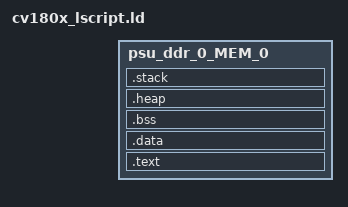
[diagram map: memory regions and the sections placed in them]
/*******************************************************************/
/*                                                                 */
/* This file is automatically generated by linker script generator.*/
/*                                                                 */
/* Version:                                 */
/*                                                                 */
/* Copyright (c) 2010-2016 Xilinx, Inc.  All rights reserved.      */
/*                                                                 */
/* Description : Cortex-A53 Linker Script                          */
/*                                                                 */
/*******************************************************************/
INCLUDE cvi_board_memmap.ld

_STACK_SIZE = DEFINED(_STACK_SIZE) ? _STACK_SIZE : 0x20000;
/* _HEAP_SIZE = DEFINED(_HEAP_SIZE) ? _HEAP_SIZE : 0x1000000; */
/*_HEAP_SIZE =  0x20000;*/

_EL0_STACK_SIZE = DEFINED(_EL0_STACK_SIZE) ? _EL0_STACK_SIZE : 1024;
_EL1_STACK_SIZE = DEFINED(_EL1_STACK_SIZE) ? _EL1_STACK_SIZE : 2048;
_EL2_STACK_SIZE = DEFINED(_EL2_STACK_SIZE) ? _EL2_STACK_SIZE : 1024;

/* Define Memories in the system */

MEMORY
{
   psu_ddr_0_MEM_0 : ORIGIN = CVIMMAP_FREERTOS_ADDR , LENGTH = CVIMMAP_FREERTOS_SIZE
}

/* Specify the default entry point to the program */

/*ENTRY(_vector_table)*/
ENTRY(_start)

/* Define the sections, and where they are mapped in memory */

SECTIONS
{
.text : {
   KEEP (*(.vectors))
   *(.text)
   *(.text.*)
   __rodata_start = .;
   *(.rodata)
   *(.rodata.*)
   *(.srodata)
   *(.srodata.*)
   __rodata_end = .;
} > psu_ddr_0_MEM_0


.data : {
   . = ALIGN(16);
   _data = .;
   __data_start = .;
   *(.sdata)
   *(.sdata.*)
   *(.data)
   *(.data.*)
   __data_end = .;
  _edata = .;
} > psu_ddr_0_MEM_0

.bss (NOLOAD) : {
   . = ALIGN(16);
   __bss_start__ = .;
   _bss = .;
   *(.bss)
   *(.bss.*)
   *(.sbss)
   *(.sbss.*)
   _ebss = .;
   __bss_end__ = .;
} > psu_ddr_0_MEM_0

/*_SDA_BASE_ = __sdata_start + ((__sbss_end - __sdata_start) / 2 );*/
    _data_lma = LOADADDR(.data);

/* Generate Stack and Heap definitions */

.heap (NOLOAD) : {
   . = ALIGN(16);
   _heap = .;
   HeapBase = .;
   _heap_start = .;
   *(.heap*)
   /*. += _HEAP_SIZE;*/
   /*_heap_size = _HEAP_SIZE; */
   _heap_end = .;
   HeapLimit = .;
} > psu_ddr_0_MEM_0

.stack (NOLOAD) : {
   . = ALIGN(16);
   __os_sys_sp_start = .;
   _stack_end_end = .;
   . += _STACK_SIZE;
   _stack_top = .;
   __os_sys_sp_end = .;
} > psu_ddr_0_MEM_0

_end = .;
}

